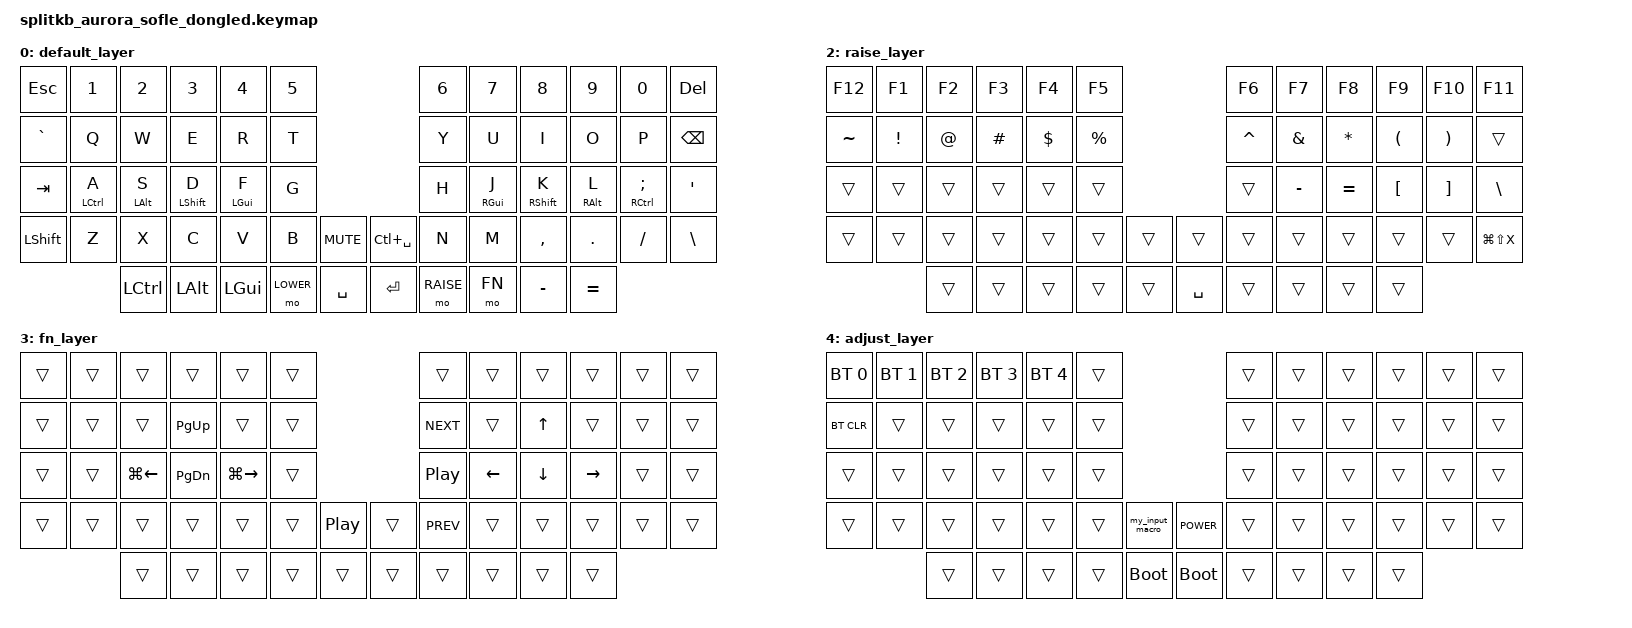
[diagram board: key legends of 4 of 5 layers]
/*
 * Copyright (c) 2023 The ZMK Contributors
 *
 * SPDX-License-Identifier: MIT
 */

#include <behaviors.dtsi>
#include <dt-bindings/zmk/keys.h>
#include <dt-bindings/zmk/bt.h>
#include <dt-bindings/zmk/ext_power.h>

/* Uncomment this block if using RGB
&led_strip {
    chain-length = <6>;
    // chain-length = <35>; // Uncomment if using both per-key and underglow LEDs
    // chain-length = <29>; // Uncomment if using only per-key LEDs.
};
 */

// Layer definitions
#define DEFAULT 0
#define LOWER   1
#define RAISE   2
#define FN      3
#define ADJUST  4

// Is this an override node?
&sensors {
    left_encoder {
        triggers-per-rotation = <72>;
    };
    right_encoder {
        triggers-per-rotation = <72>;
    };
};

/ {
    sensors {
        compatible = "zmk,keymap-sensors";
        sensors = <&left_encoder &right_encoder>;
        triggers-per-rotation = <72>;
    };

    behaviors {
        bhm: balanced_homerow_mods {
            compatible = "zmk,behavior-hold-tap";
            #binding-cells = <2>;
            tapping-term-ms = <200>;
            quick-tap-ms = <0>;
            flavor = "balanced";
            bindings = <&kp>, <&kp>;
        };

        rot_kp: sensor_rotate_kp {
            compatible = "zmk,behavior-sensor-rotate-var";
            #sensor-binding-cells = <2>;
            bindings = <&kp>, <&kp>;
        };
    };

    conditional_layers {
        compatible = "zmk,conditional-layers";
        tri_layer {
            if-layers = <LOWER RAISE>;
            then-layer = <ADJUST>;
        };
    };

    macros {
        ZMK_MACRO(my_input_macro,
            wait-ms = <30>;
            tap-ms = <40>;
            bindings
                = <&macro_press &kp LSHFT>
                , <&macro_tap &kp W>
                , <&macro_release &kp LSHFT>
                , <&macro_tap &kp H &kp A &kp T &kp SPACE &kp T &kp H &kp E &kp SPACE>
                , <&macro_press &kp LSHFT>
                , <&macro_tap &kp M>
                , <&macro_release &kp LSHFT>
                , <&macro_tap &kp A &kp C>
                , <&macro_tap &kp RET>
                ;
        )
    };

    keymap {
        compatible = "zmk,keymap";

        default_layer {
            bindings = <
&kp ESC   &kp N1        &kp N2        &kp N3          &kp N4        &kp N5                            &kp N6 &kp N7       &kp N8         &kp N9        &kp N0         &kp DEL
&kp GRAVE &kp Q         &kp W         &kp E           &kp R         &kp T                             &kp Y  &kp U        &kp I          &kp O         &kp P          &kp BSPC
&kp TAB   &bhm LCTRL A  &bhm LALT S   &bhm LSHIFT D   &bhm LGUI F   &kp G                             &kp H  &bhm RGUI J  &bhm RSHIFT K  &bhm RALT L   &bhm RCTRL SEMI &kp SQT
&kp LSHFT &kp Z         &kp X         &kp C           &kp V         &kp B      &kp C_MUTE     &kp LC(SPACE) &kp N  &kp M        &kp COMMA      &kp DOT       &kp FSLH   &kp BSLH
                        &kp LCTRL &kp LALT            &kp LGUI      &mo LOWER  &kp SPACE      &kp RET  &mo RAISE  &mo FN        &kp MINUS      &kp EQUAL
            >;
//            sensor-bindings = <&inc_dec_kp C_VOL_DN C_VOL_UP &inc_dec_kp LEFT RIGHT>;
//            sensor-bindings = <&rot_kp C_VOL_DN C_VOL_UP>;
            sensor-bindings = <&inc_dec_kp C_VOL_DN C_VOL_UP>;
        };

        lower_layer {
            bindings = <
&trans    &trans    &trans    &trans    &trans     &trans                     &trans    &trans     &trans     &trans    &trans    &kp LC(DEL)
&trans    &trans    &trans    &trans    &trans     &trans                     &trans    &trans     &trans     &kp LPAR  &kp RPAR  &kp LC(BSPC)
&trans    &trans    &trans    &trans    &trans     &kp LPAR              &kp RPAR  &kp UNDER  &kp PLUS  &kp LBRC  &kp RBRC  &kp PIPE
&trans    &trans    &trans    &trans    &trans     &kp LBRC  &kp C_PP     &trans    &kp RBRC  &trans     &trans    &trans    &trans
                    &trans    &trans    &trans     &trans    &kp RET      &kp LS(INS) &trans   &trans    &trans    &trans
            >;
            sensor-bindings = <&inc_dec_kp C_PREV C_NEXT>;
        };

        raise_layer {
            bindings = <
&kp F12   &kp F1    &kp F2    &kp F3     &kp F4     &kp F5                     &kp F6    &kp F7     &kp F8     &kp F9    &kp F10   &kp F11
&kp TILDE &kp EXCL  &kp AT    &kp HASH   &kp DLLR   &kp PRCNT                  &kp CARET &kp AMPS   &kp STAR   &kp LPAR  &kp RPAR  &trans
&trans    &trans    &trans    &trans     &trans     &trans                      &trans    &kp MINUS  &kp EQUAL  &kp LBKT  &kp RBKT  &kp BSLH
&trans    &trans    &trans    &trans     &trans     &trans    &trans           &trans    &trans     &trans     &trans    &trans    &trans    &kp LG(LS(X))
                    &trans    &trans     &trans     &trans    &trans           &kp SPACE &trans     &trans     &trans     &trans
            >;
            sensor-bindings = <&inc_dec_kp C_VOL_UP C_VOL_DN>;
        };

        fn_layer {
            bindings = <
&trans    &trans    &trans       &trans     &trans        &trans                            &trans    &trans     &trans     &trans    &trans    &trans
&trans    &trans    &trans       &kp PG_UP  &trans        &trans                            &kp C_NEXT &trans    &kp UP     &trans    &trans    &trans
&trans    &trans    &kp LG(LEFT) &kp PG_DN  &kp LG(RIGHT) &trans                            &kp C_PP  &kp LEFT   &kp DOWN   &kp RIGHT &trans    &trans
&trans    &trans    &trans       &trans     &trans        &trans    &kp C_PP      &trans    &kp C_PREV &trans     &trans    &trans    &trans    &trans
                    &trans       &trans     &trans        &trans    &trans        &trans    &trans     &trans     &trans     &trans
            >;
            sensor-bindings = <&inc_dec_kp C_PREV C_NEXT>;
        };

        adjust_layer {
            bindings = <
&bt BT_SEL 0 &bt BT_SEL 1 &bt BT_SEL 2 &bt BT_SEL 3 &bt BT_SEL 4 &trans                                 &trans       &trans    &trans     &trans    &trans    &trans
&bt BT_CLR   &trans       &trans       &trans       &trans       &trans                                 &trans       &trans    &trans     &trans    &trans    &trans
&trans       &trans       &trans       &trans       &trans       &trans                                 &trans       &trans    &trans     &trans    &trans    &trans
&trans       &trans       &trans       &trans       &trans       &trans    &my_input_macro  &kp C_POWER &trans       &trans    &trans     &trans    &trans    &trans
                          &trans       &trans       &trans       &trans    &bootloader      &bootloader  &trans     &trans    &trans     &trans
            >;
            sensor-bindings = <&inc_dec_kp C_VOL_DN C_VOL_UP>;
        };
    };
};
